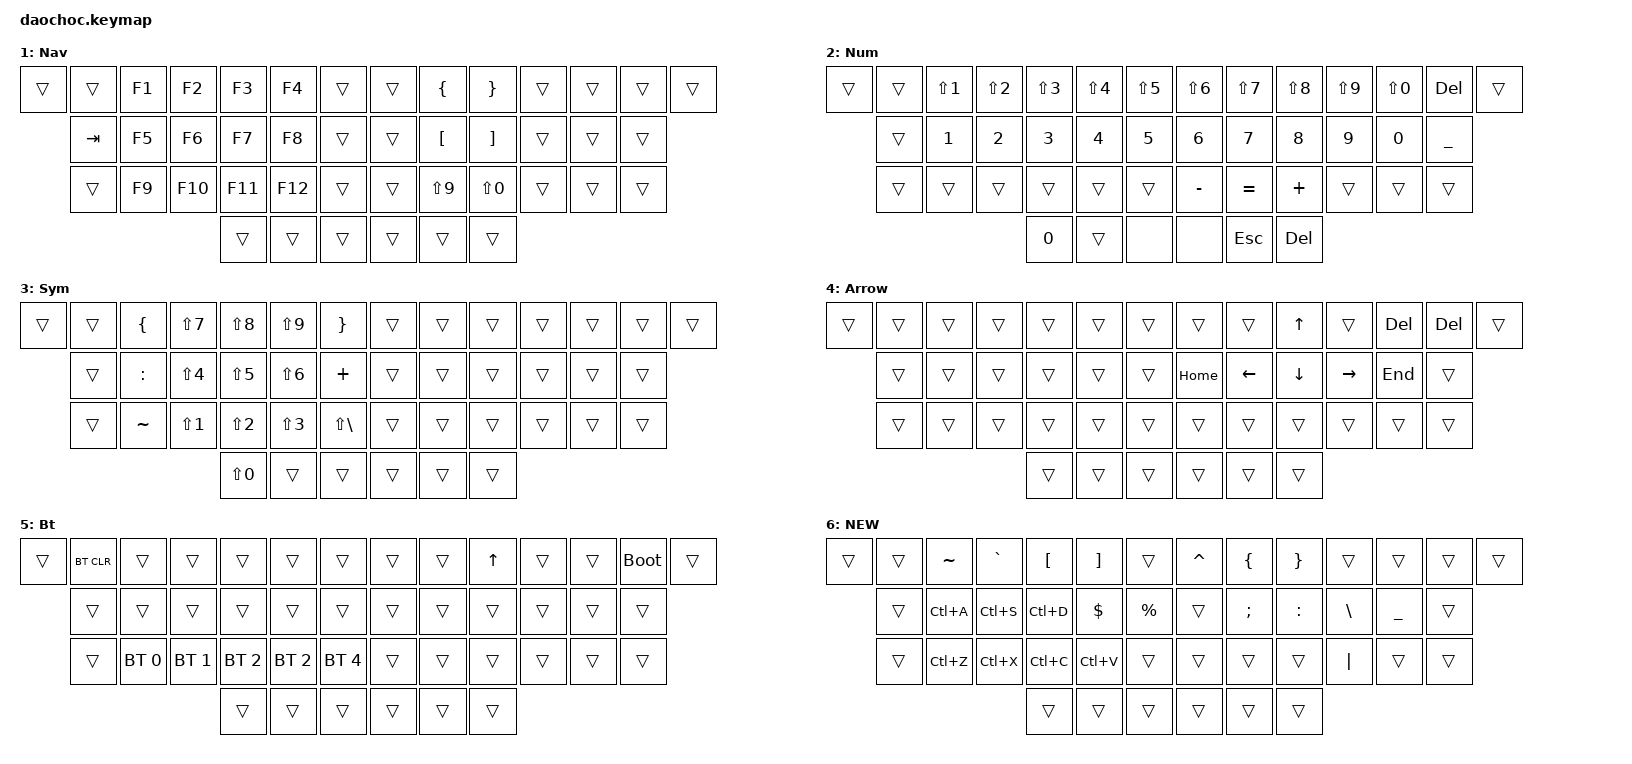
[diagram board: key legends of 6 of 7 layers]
/*
 * Copyright (c) 2021 Rafael Yumagulov
 *
 * SPDX-License-Identifier: MIT
 */

#include <behaviors.dtsi>
#include <dt-bindings/zmk/keys.h>
#include <dt-bindings/zmk/bt.h>
#include <dt-bindings/zmk/outputs.h>

#define DEF 0
#define NAV_L 1
#define NUM_L 2
#define SYM_L 3
#define ARROW_L 4
#define BT_L 5
#define NEW_L 6

// Home row mods macro
#define HRML(k1,k2,k3,k4) &ht LSHFT k1  &ht LALT k2  &ht LCTRL k3  &ht LGUI k4
#define HRMR(k1,k2,k3,k4) &ht RGUI k1  &ht RCTRL k2  &ht RALT k3  &ht RSHFT k4

#define COMBO(NAME, KEYPOS) \
  combo_##NAME { \
      timeout-ms = <40>; \
      key-positions = <KEYPOS>; \
      bindings = <&kp NAME>; \
  };


&lt { quick_tap_ms = <200>; };
&mt { quick_tap_ms = <200>; };

/ {
    behaviors {
        bhm: balanced_homerow_mods {
            compatible = "zmk,behavior-hold-tap";
            label = "HOMEROW_MODS";
            #binding-cells = <2>;
            tapping-term-ms = <200>;    // <---[[moderate duration]]
            quick-tap-ms = <0>;
            flavor = "balanced";
            bindings = <&kp>, <&kp>;
        };
        ht: hold_tap {
            label = "hold_tap";
            compatible = "zmk,behavior-hold-tap";
            #binding-cells = <2>;
            flavor = "tap-preferred";
            tapping-term-ms = <220>;
            quick-tap-ms = <150>;
            global-quick-tap;
            bindings = <&kp>, <&kp>;
        };
    };

    conditional_layers {
        compatible = "zmk,conditional-layers";
	    tri_layer {
	      if-layers = <NAV_L NUM_L>;
	      then-layer = <SYM_L>;
	    };
    };

        combos {
      compatible = "zmk,combos";
      
      // Left-hand combos
      COMBO(TAB, 17 18)
      //COMBO(LEFT_BRACE, 2 3)

      // Right-hand combos

    };




        //             ╭──────────┬──────────┬──────────┬──────────┬──────────┬──────────╮   ╭──────────┬──────────┬──────────┬──────────┬──────────┬──────────╮
        //             │  1       │  2       │  3       │  4       │  5       │  6       │   │  7       │  8       │  9       │ 10       │ 11       │ 12       │
        //  ╭─────────────────────┼──────────┬──────────┼──────────┼──────────┼──────────┤   ├──────────┼──────────┼──────────┼──────────┼──────────┬──────────┼──────────╮
        //  │ 0        │ 14       │ 15       │ 16       │ 17       │ 18       │ 19       │   │ 20       │ 21       │ 22       │ 23       │ 24       │ 25       │ 13       │
        //  ╰─────────────────────┼──────────┬──────────┼──────────┼──────────┼──────────┤   ├──────────┼──────────┼──────────┼──────────┼──────────┬──────────┼──────────╯
        //             │ 26       │ 27       │ 28       │ 29       │ 30       │ 31       │   │ 32       │ 33       │ 34       │ 35       │ 36       │ 37       │
        //             ╰──────────┴──────────┴──────────┴──────────┼──────────┼──────────┤   ├──────────┼──────────┼──────────┼──────────┴──────────┴──────────╯
        //                                              | 38       | 39       | 40       |   | 41       | 42       | 43       |
        //                                              ╰──────────┴──────────┴──────────╯   ╰──────────┴──────────┴──────────╯


        keymap {
                compatible = "zmk,keymap";
                default_layer {


        //             ╭──────────┬──────────┬──────────┬──────────┬──────────┬──────────╮   ╭──────────┬──────────┬──────────┬──────────┬──────────┬──────────╮
        //             │  1       │  Q       │  W       │  E       │  R       │  T       │   │  7       │  8       │  9       │ 10       │ 11       │ 12       │
        //  ╭─────────────────────┼──────────┬──────────┼──────────┼──────────┼──────────┤   ├──────────┼──────────┼──────────┼──────────┼──────────┬──────────┼──────────╮
        //  │ 0        │ 14       │ 15       │ 16       │  D       │  F       │  G       │   │ 20       │ 21       │ 22       │ 23       │ 24       │ 25       │ 13       │
        //  ╰─────────────────────┼──────────┬──────────┼──────────┼──────────┼──────────┤   ├──────────┼──────────┼──────────┼──────────┼──────────┬──────────┼──────────╯
        //             │ 26       │ 27       │ 28       │ 29       │ 30       │ 31       │   │ 32       │ 33       │ 34       │ 35       │ 36       │ 37       │
        //             ╰──────────┴──────────┴──────────┴──────────┼──────────┼──────────┤   ├──────────┼──────────┼──────────┼──────────┴──────────┴──────────╯
        //                                              | 38       | 39       | 40       |   | 41       | 42       | 43       |
        //                                              ╰──────────┴──────────┴──────────╯   ╰──────────┴──────────┴──────────╯

                    
// --------------------------------------------------------------------------------------
//  | GUI  | ESC  |  Q  |  W  |  E  |  R  |  T  |    |  Y  |  U   |  I  |  O  |  P  |  \   |  GUI |
//         | CTRL |  A  |  S  |  D  |  F  |  G  |    |  H  |  J   |  K  |  L  |  '  |  ;  |  
//         |LSHFT |  Z  |  X  |  C  |  V  |  B  |    |  N  |  M   |  ,  |  .  |  /  |  `   |
//                      | ALT | SPC | SPC |     |BKSP| ENT | GUI  |
// --------------------------------------------------------------------------------------
                        bindings = <
&kp LGUI &kp ESC   &kp Q   &kp W   &kp E   &kp R    &kp T    &kp Y   &kp U    &kp I       &kp O     &kp P      &kp BSLH  &kp RGUI
         &kp LCTRL HRML(A,   S,     D,      F)      &kp G    &kp H   &kp J    &kp K       &kp L     &ht RSHFT SQT  &kp SEMI   
         &kp LSHFT &kp Z   &kp X   &kp C   &kp V    &kp B    &kp N   &kp M    &kp COMMA   &kp DOT   &mt RSHIFT FSLH   &mt RSHIFT GRAVE
              &kp LALT   &lt NAV_L ESC   &lt NEW_L SPACE   &lt NUM_L BKSP  &lt ARROW_L RET    &lt BT_L LGUI
                        >;
                };
   nav_layer {
            label = "Nav";
            bindings = <
// --------------------------------------------------------------------------------------
//   | ESC  |  F1 |  F2 |  F3 |  F4 |   |    |  { |  }   |     |     |     |      | 
//   | CTRL |  F5 |  F6 |  F7 |  F8 |   |    |  [ |  ]   |     |     |     |      |
//   |LSHFT |  F9 | F10 | F11 | F12 |   |    |  ( |  )   |     |     |     |      |
//                |     |     |     |   |    |    |      |     |     |
// --------------------------------------------------------------------------------------
&trans &trans   &kp F1 &kp F2  &kp F3  &kp F4  &trans &trans  &kp LBRC    &kp RBRC  &trans &trans &trans  &trans
&kp TAB  &kp F5 &kp F6  &kp F7  &kp F8  &trans &trans  &kp LBKT    &kp RBKT  &trans &trans &trans 
&trans   &kp F9 &kp F10 &kp F11 &kp F12 &trans &trans  &kp LS(N9)  &kp LS(N0)    &trans &trans &trans 
             &trans      &trans          &trans       &trans    &trans  &trans         
            >;
        };


        num_layer {
            label = "Num";
            bindings = <
// --------------------------------------------------------------------------------------
//   |    |  !  |  @  |  #  |  $  |  %  |    | ^  |  &   |  *  |  (  |  )  |  DEL | 
//   |    |  1  |  2  |  3  |  4  |  5  |    | 6  |  7   |  8  |  9  |  0  |  _   |
//   |    |     |     |     |     |     |    | -  |  =   |  +  |      |    |      |
// --------------------------------------------------------------------------------------
&trans &trans   &kp LS(N1)   &kp LS(N2) &kp LS(N3) &kp LS(N4)  &kp LS(N5) &kp LS(N6) &kp LS(N7)  &kp LS(N8)  &kp LS(N9)  &kp LS(N0) &kp DEL     &trans
&trans   &kp N1       &kp N2     &kp N3     &kp N4      &kp N5     &kp N6     &kp N7      &kp N8      &kp N9      &kp N0     &kp UNDER
&trans   &trans       &trans     &trans     &trans      &trans     &kp MINUS  &kp EQUAL   &kp PLUS    &trans     &trans      &trans 
             &kp N0      &trans    &none         &none     &kp ESC        &kp DEL     
            >;
        };

        sym_layer {
            label = "Sym";
            bindings = <
&trans &trans     &kp LBRC   &kp LS(N7) &kp LS(N8)  &kp LS(N9)   &kp RBRC     &trans     &trans    &trans       &trans       &trans     &trans &trans
&trans     &kp COLON  &kp LS(N4) &kp LS(N5)  &kp LS(N6)   &kp PLUS     &trans     &trans    &trans       &trans       &trans     &trans
&trans     &kp TILDE  &kp LS(N1) &kp LS(N2)  &kp LS(N3)   &kp LS(BSLH) &trans     &trans    &trans       &trans       &trans     &trans
                  &kp LS(N0)      &trans          &trans       &trans    &trans  &trans         
            >;
        };

        arrow_layer {
            label = "Arrow";
            bindings = <
&trans &trans  &trans  &trans  &trans  &trans  &trans  &trans  &trans  &kp UP  &trans &kp DEL &kp DEL &trans
&trans  &trans  &trans  &trans  &trans  &trans  &kp HOME  &kp LEFT  &kp DOWN  &kp RIGHT  &kp END  &trans  
&trans  &trans  &trans  &trans  &trans  &trans  &trans  &trans  &trans  &trans  &trans  &trans  
                &trans      &trans          &trans       &trans    &trans  &trans         
            >;
        };


bt_layer {
            label = "Bt";
            bindings = <
&trans &bt BT_CLR  &trans  &trans  &trans  &trans  &trans  &trans  &trans  &kp UP  &trans  &trans &bootloader   &trans
&trans  &trans  &trans  &trans  &trans  &trans   &trans  &trans &trans &trans &trans &trans
&trans  &bt BT_SEL 0 &bt BT_SEL 1  &bt BT_SEL 2   &bt BT_SEL 2   &bt BT_SEL 4   &trans  &trans  &trans  &trans  &trans  &trans  
                &trans      &trans          &trans       &trans    &trans  &trans         
            >;
        };

new_layer {
            label = "NEW";
            bindings = <
           //╭──────────┬──────────┬──────────┬──────────┬──────────╮   ╭──────────┬──────────┬──────────┬──────────┬──────────╮
           //│  ~       │   `      │  [       │  ]       │          │   │  ^       │  {       │  }       │          │          │
&trans &trans &kp TILDE   &kp GRAVE  &kp LBKT   &kp RBKT    &trans        &kp CARET  &kp LBRC   &kp RBRC   &trans      &trans    &trans  &trans 
           //├──────────┼──────────┼──────────┼──────────┼──────────┤   ├──────────┼──────────┼──────────┼──────────┼──────────┤
           //│ CTRL A   │ CTRL S   │ CTRL D   │  $       │  %       │   │          │   ;      │   :      │  \       │   _      │
&trans         &kp LC(A)  &kp LC(S) &kp LC(D)  &kp DLLR   &kp PRCNT      &trans    &kp SEMI   &kp COLON  &kp BSLH   &kp UNDER    &trans 
           //├──────────┼──────────┼──────────┼──────────┼──────────┤   ├──────────┼──────────┼──────────┼──────────┼──────────┤
           //│ CTRL Z   │ CTRL X   │ CTRL C   │ CTRL V   │          │   │          │          │          │  │       │          │
&trans         &kp LC(Z) &kp LC(X)   &kp LC(C)  &kp LC(V)   &trans         &trans    &trans     &trans     &kp PIPE     &trans   &trans 
           //╰──────────┴──────────┴──────────┼──────────┼──────────┤   ├──────────┼──────────┼──────────┴──────────┴──────────╯
                                    &trans       &trans     &trans         &trans     &trans     &trans 
           //          
 
        >;
       };
    };
};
